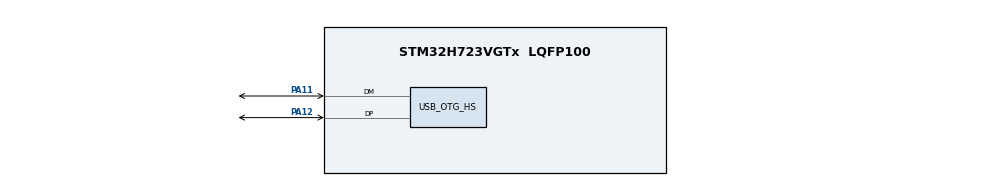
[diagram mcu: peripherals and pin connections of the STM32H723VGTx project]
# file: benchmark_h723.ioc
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CORTEX_M7.Enable_Spec=__NULL
CORTEX_M7.default_mode_Activation=1
Mcu.Family=STM32H7
Mcu.Name=STM32H723VGTx
Mcu.Package=LQFP100
NVIC.PriorityGroup=NVIC_PRIORITYGROUP_4
PA11.Mode=Device_Only_FS
PA11.Signal=USB_OTG_HS_DM
PA12.Mode=Device_Only_FS
PA12.Signal=USB_OTG_HS_DP
PA13(JTMS/SWDIO).Mode=Trace_Asynchronous_SW
PA13(JTMS/SWDIO).Signal=DEBUG_JTMS-SWDIO
PA14(JTCK/SWCLK).Mode=Trace_Asynchronous_SW
PA14(JTCK/SWCLK).Signal=DEBUG_JTCK-SWCLK
PB3(JTDO/TRACESWO).Mode=Trace_Asynchronous_SW
PB3(JTDO/TRACESWO).Signal=DEBUG_JTDO-SWO
PH0-OSC_IN.Mode=HSE-External-Oscillator
PH0-OSC_IN.Signal=RCC_OSC_IN
PH1-OSC_OUT.Mode=HSE-External-Oscillator
PH1-OSC_OUT.Signal=RCC_OSC_OUT
ProjectManager.HeapSize=0x200
ProjectManager.StackSize=0x400
ProjectManager.TargetToolchain=CMake
RCC.ADCFreq_Value=50390625
RCC.APB1Freq_Value=137500000
RCC.APB2Freq_Value=137500000
RCC.APB3Freq_Value=137500000
RCC.APB4Freq_Value=137500000
RCC.CortexFreq_Value=550000000
RCC.D1PPRE=RCC_APB3_DIV2
RCC.D2PPRE1=RCC_APB1_DIV2
RCC.D2PPRE2=RCC_APB2_DIV2
RCC.D3PPRE=RCC_APB4_DIV2
RCC.DIVM1=2
RCC.DIVN1=44
RCC.DIVP1=1
RCC.DIVQ1=5
RCC.HCLKFreq_Value=275000000
RCC.HPRE=RCC_HCLK_DIV2
RCC.PLLFRACN=0
RCC.PLLSourceVirtual=RCC_PLLSOURCE_HSE
RCC.SYSCLKFreq_VALUE=550000000
RCC.SYSCLKSource=RCC_SYSCLKSOURCE_PLLCLK
RCC.USBCLockSelection=RCC_USBCLKSOURCE_HSI48
RCC.USBFreq_Value=48000000
USB_OTG_HS.VirtualMode-Device_Only_FS=Device_Only_FS
VP_MEMORYMAP_VS_MEMORYMAP.Mode=CurAppReg
VP_RCC_USB.Mode=USB_HS
board=custom

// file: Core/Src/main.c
/* USER CODE BEGIN Header */
/**
  ******************************************************************************
  * @file           : main.c
  * @brief          : Main program body
  ******************************************************************************
  * @attention
  *
  * Copyright (c) 2026 STMicroelectronics.
  * All rights reserved.
  *
  * This software is licensed under terms that can be found in the LICENSE file
  * in the root directory of this software component.
  * If no LICENSE file comes with this software, it is provided AS-IS.
  *
  ******************************************************************************
  */
/* USER CODE END Header */
#include "main.h"
#include "usb_otg.h"
#include "gpio.h"

/* USER CODE BEGIN Includes */
#include "bench.h"
#include "bench_plat.h"
#ifdef BENCH_WITH_TINYUSB
#include "usb_glue.h"
#include "abf_cdc.h"
#include "rnnoise_place.h"
#include "tusb.h"
#endif
/* USER CODE END Includes */

void SystemClock_Config(void);
static void MPU_Config(void);

int main(void)
{

  /* USER CODE BEGIN 1 */
  /* Placement variables (bench_place.ld.in): copy ITCM code and AXI weights
   * before the caches come up and before anything moved can run. First. */
  rnnoise_place_init();

  /* USER CODE END 1 */

  /* MPU Configuration--------------------------------------------------------*/
  MPU_Config();

  /* MCU Configuration--------------------------------------------------------*/

  /* Reset of all peripherals, Initializes the Flash interface and the Systick. */
  HAL_Init();

  /* USER CODE BEGIN Init */

  /* Cache and MPU configuration. Deliberately AFTER CubeMX's MPU_Config(),
   * which enables the MPU with the privileged default map and no regions:
   * bench_plat_init() disables it again explicitly, so the final state is
   * ours and is recorded in g_plat.mpu_ctrl rather than inherited from a
   * generated file. Caches are enabled here per BENCH_ICACHE/BENCH_DCACHE.
   * Both are measured variables on this tier -- see bench_plat.h. */
  bench_plat_init();

  /* USER CODE END Init */

  /* Configure the system clock */
  SystemClock_Config();

  /* Initialize all configured peripherals */
  MX_GPIO_Init();
  /* MX_USB_OTG_HS_PCD_Init() is deliberately NOT called -- TinyUSB drives the
   * OTG registers directly and HAL_PCD_Init() would reconfigure the same core
   * underneath it, at a cost of ~1.2 KB of SRAM for the handle alone.
   *
   * REGENERATION HAZARD: CubeMX puts this call back, and on the H7 (unlike the
   * F411) the generated HAL_PCD_MspInit() is also where the USB kernel clock
   * and the transceiver's 3.3 V supply get enabled. Those have been moved into
   * usb/usb_glue.c. If USB stops enumerating after a regeneration, check that
   * this call is still absent and that usb_glue_init() is still being called. */
  /* USER CODE BEGIN 2 */

  /* Record the configuration the probe is about to run under, read back from
   * hardware rather than assumed from the #defines that asked for it. */
  bench_plat_snapshot();

  /* Run the throughput probe once, at boot, before anything else can compete
   * for the core. Results land in g_bench. */
#ifdef BENCH_WITH_PROBE
  bench_run_all();
#else
  /* Streaming image: no probe, but the cycle counter must run for the ABF1
   * tick source. */
  g_bench.cpu_hz = SystemCoreClock;
  g_bench.done   = bench_dwt_init() ? 1u : 0u;
#endif

#ifdef BENCH_WITH_TINYUSB
  /* USB comes up only AFTER the probe. The probe masks interrupts around every
   * timed region, and an enumeration storm arriving mid-suite is exactly the
   * I/O-inside-a-measurement the harness rules forbid. Do not reorder. */
  usb_glue_abf_init();   /* image CRC + HELLO identity + binding, before enumeration */
  usb_glue_init();
#endif

  /* USER CODE END 2 */

  /* Infinite loop */
  while (1)
  {

    /* USER CODE BEGIN 3 */
#ifdef BENCH_WITH_TINYUSB
    tud_task();
    abf_cdc_service();   /* task 7's framing; never blocks, one packet per call */
#endif
    /* Refreshes g_plat.crs_isr / crs_syncok_seen. CRS can only lock once the
     * host is sending SOF, i.e. after enumeration, so this has to be polled
     * from the loop rather than sampled once at boot. It is what decides
     * whether CubeMX's RCC_CRS_SYNC_SOURCE_USB2 is correct on a part whose
     * only USB instance is USB1_OTG_HS. */
    bench_plat_poll();
  }
  /* USER CODE END 3 */
}

void SystemClock_Config(void)
{
  RCC_OscInitTypeDef RCC_OscInitStruct = {0};
  RCC_ClkInitTypeDef RCC_ClkInitStruct = {0};
  RCC_CRSInitTypeDef RCC_CRSInitStruct = {0};

  /** Supply configuration update enable
  */
  HAL_PWREx_ConfigSupply(PWR_LDO_SUPPLY);

  /** Configure the main internal regulator output voltage
  */
  __HAL_PWR_VOLTAGESCALING_CONFIG(PWR_REGULATOR_VOLTAGE_SCALE0);

  while(!__HAL_PWR_GET_FLAG(PWR_FLAG_VOSRDY)) {}

  /** Initializes the RCC Oscillators according to the specified parameters
  * in the RCC_OscInitTypeDef structure.
  */
  RCC_OscInitStruct.OscillatorType = RCC_OSCILLATORTYPE_HSI48|RCC_OSCILLATORTYPE_HSE;
  RCC_OscInitStruct.HSEState = RCC_HSE_ON;
  RCC_OscInitStruct.HSI48State = RCC_HSI48_ON;
  RCC_OscInitStruct.PLL.PLLState = RCC_PLL_ON;
  RCC_OscInitStruct.PLL.PLLSource = RCC_PLLSOURCE_HSE;
  RCC_OscInitStruct.PLL.PLLM = 2;
  RCC_OscInitStruct.PLL.PLLN = 44;
  RCC_OscInitStruct.PLL.PLLP = 1;
  RCC_OscInitStruct.PLL.PLLQ = 5;
  RCC_OscInitStruct.PLL.PLLR = 2;
  RCC_OscInitStruct.PLL.PLLRGE = RCC_PLL1VCIRANGE_3;
  RCC_OscInitStruct.PLL.PLLVCOSEL = RCC_PLL1VCOWIDE;
  RCC_OscInitStruct.PLL.PLLFRACN = 0;
  if (HAL_RCC_OscConfig(&RCC_OscInitStruct) != HAL_OK)
  {
    Error_Handler();
  }

  /** Initializes the CPU, AHB and APB buses clocks
  */
  RCC_ClkInitStruct.ClockType = RCC_CLOCKTYPE_HCLK|RCC_CLOCKTYPE_SYSCLK
                              |RCC_CLOCKTYPE_PCLK1|RCC_CLOCKTYPE_PCLK2
                              |RCC_CLOCKTYPE_D3PCLK1|RCC_CLOCKTYPE_D1PCLK1;
  RCC_ClkInitStruct.SYSCLKSource = RCC_SYSCLKSOURCE_PLLCLK;
  RCC_ClkInitStruct.SYSCLKDivider = RCC_SYSCLK_DIV1;
  RCC_ClkInitStruct.AHBCLKDivider = RCC_HCLK_DIV2;
  RCC_ClkInitStruct.APB3CLKDivider = RCC_APB3_DIV2;
  RCC_ClkInitStruct.APB1CLKDivider = RCC_APB1_DIV2;
  RCC_ClkInitStruct.APB2CLKDivider = RCC_APB2_DIV2;
  RCC_ClkInitStruct.APB4CLKDivider = RCC_APB4_DIV2;

  if (HAL_RCC_ClockConfig(&RCC_ClkInitStruct, FLASH_LATENCY_3) != HAL_OK)
  {
    Error_Handler();
  }

  /** Enable the SYSCFG APB clock
  */
  __HAL_RCC_CRS_CLK_ENABLE();

  /** Configures CRS
  */
  RCC_CRSInitStruct.Prescaler = RCC_CRS_SYNC_DIV1;
  RCC_CRSInitStruct.Source = RCC_CRS_SYNC_SOURCE_USB2;
  RCC_CRSInitStruct.Polarity = RCC_CRS_SYNC_POLARITY_RISING;
  RCC_CRSInitStruct.ReloadValue = __HAL_RCC_CRS_RELOADVALUE_CALCULATE(48000000,1000);
  RCC_CRSInitStruct.ErrorLimitValue = 34;
  RCC_CRSInitStruct.HSI48CalibrationValue = 32;

  HAL_RCCEx_CRSConfig(&RCC_CRSInitStruct);
}

 /* MPU Configuration */

void MPU_Config(void)
{

  /* Disables the MPU */
  HAL_MPU_Disable();

  /* Enables the MPU */
  HAL_MPU_Enable(MPU_PRIVILEGED_DEFAULT);

}

void Error_Handler(void)
{
  __disable_irq();
  while (1)
  {
  }
}
